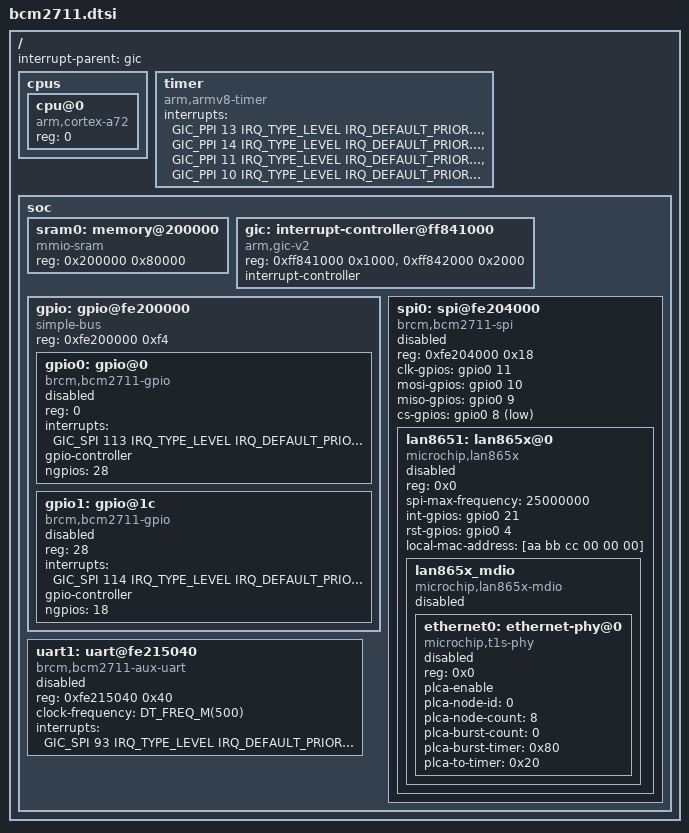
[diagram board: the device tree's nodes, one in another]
/*
 * Copyright 2023 honglin leng <a909204013@gmail.com>
 *
 * SPDX-License-Identifier: Apache-2.0
 */

#include <mem.h>
#include <freq.h>

#include <arm64/armv8-a.dtsi>
#include <zephyr/dt-bindings/interrupt-controller/arm-gic.h>
#include <zephyr/dt-bindings/gpio/gpio.h>

/ {
	cpus {
		#address-cells = <1>;
		#size-cells = <0>;

		cpu@0 {
			device_type = "cpu";
			compatible = "arm,cortex-a72";
			reg = <0>;
		};
	};

	interrupt-parent = <&gic>;

	timer {
		compatible = "arm,armv8-timer";
		interrupts = <GIC_PPI 13 IRQ_TYPE_LEVEL
			      IRQ_DEFAULT_PRIORITY>,
			     <GIC_PPI 14 IRQ_TYPE_LEVEL
			      IRQ_DEFAULT_PRIORITY>,
			     <GIC_PPI 11 IRQ_TYPE_LEVEL
			      IRQ_DEFAULT_PRIORITY>,
			     <GIC_PPI 10 IRQ_TYPE_LEVEL
			      IRQ_DEFAULT_PRIORITY>;
	};

	soc {
		sram0: memory@200000 {
			device_type = "memory";
			compatible = "mmio-sram";
			reg = <0x200000 0x80000>;
		};

		gic: interrupt-controller@ff841000 {
			compatible = "arm,gic-v2", "arm,gic";
			reg = <0xff841000 0x1000>,
			      <0xff842000 0x2000>;
			interrupt-controller;
			#interrupt-cells = <4>;
			status = "okay";
		};

		gpio: gpio@fe200000 {
			compatible = "simple-bus";
			reg = <0xfe200000 0xf4>;
			#address-cells = <1>;
			#size-cells = <0>;

			/* GPIO 0 ~ 27 */
			gpio0: gpio@0 {
				compatible = "brcm,bcm2711-gpio";
				reg = <0>;
				interrupts = <GIC_SPI 113 IRQ_TYPE_LEVEL
					      IRQ_DEFAULT_PRIORITY>;
				gpio-controller;
				#gpio-cells = <2>;
				ngpios = <28>;
				status = "disabled";
			};

			/* GPIO 28 ~ 45 */
			gpio1: gpio@1c {
				compatible = "brcm,bcm2711-gpio";
				reg = <28>;
				interrupts = <GIC_SPI 114 IRQ_TYPE_LEVEL
					      IRQ_DEFAULT_PRIORITY>;
				gpio-controller;
				#gpio-cells = <2>;
				ngpios = <18>;
				status = "disabled";
			};
		};

		uart1: uart@fe215040 {
			compatible = "brcm,bcm2711-aux-uart";
			reg = <0xfe215040 0x40>;
			clock-frequency = <DT_FREQ_M(500)>;
			interrupts = <GIC_SPI 93 IRQ_TYPE_LEVEL
				      IRQ_DEFAULT_PRIORITY>;
			status = "disabled";
		};

		spi0: spi@fe204000 {
			compatible = "brcm,bcm2711-spi";
			reg = <0xfe204000 0x18>;
			status = "disabled";

			#address-cells = <1>;
			#size-cells = <0>;

			clk-gpios = <&gpio0 11 GPIO_ACTIVE_HIGH>;
			mosi-gpios = <&gpio0 10 GPIO_ACTIVE_HIGH>;
			miso-gpios = <&gpio0 9 GPIO_ACTIVE_HIGH>;
			cs-gpios = <&gpio0 8 GPIO_ACTIVE_LOW>;

			lan8651: lan865x@0 {
				compatible = "microchip,lan865x";
				reg = <0x0>;
				spi-max-frequency = <25000000>;
				int-gpios = <&gpio0 21 0>; // TODO: gpio 23 is used by T32
				rst-gpios = <&gpio0 4 0>;
				local-mac-address = [aa bb cc 00 00 00];
				status = "disabled";
				lan865x_mdio: lan865x_mdio {
					compatible = "microchip,lan865x-mdio";
					status = "disabled";
					#address-cells = <1>;
					#size-cells = <0>;
					ethernet0: ethernet-phy@0 {
						compatible = "microchip,t1s-phy";
						reg = <0x0>;
						plca-enable;
						plca-node-id = <0>;
						plca-node-count = <8>;
						plca-burst-count = <0>;
						plca-burst-timer = <0x80>;
						plca-to-timer = <0x20>;
						status = "disabled";
					};
				};
			};
		};
	};
};
